# Q32M210 register map
File version: 1.0
Precision 32-bit mixed signal microcontroller
Registers are 32-bit, read-write, no defined reset value unless marked. A register's access mark holds for its fields unless they carry their own. Offsets are from the block's base; lines under a group give offsets from that group; [hi:lo] are bit positions; {n}, {i} and the like mark numbered series; 'fields as' and 'values as' point back to an identical list; <NAME> marks a mode.

## Memory map
0x40000008 Analog_Front-End blocks up to offset 0xF4
0x40000200 DMA_Controller_Configuration_and_Control blocks up to offset 0x94
0x40000300 UART0_Interface_Configuration_and_Control size 0x14
0x40000400 UART1_Interface_Configuration_and_Control size 0x14
0x40000500 GPIO_and_LCD_Driver_Configuration_and_Control blocks up to offset 0x70
0x40000600 SPI0_Interface_Configuration_and_Control size 0x18
0x40000700 SPI1_Interface_Configuration_and_Control size 0x18
0x40000800 PCM_Interface_Configuration_and_Control size 0xC
0x40000900 I2C_Interface_Configuration_and_Control blocks up to offset 0x20
0x40000A00 CRC_Generator_Control size 0x1C
0x40000B00 USB_Interface size 0x4
0x40000C00 Timer_0_to_3_Configuration_and_Control size 0x14
0x40000D00 Watchdog_Timer_Configuration_and_Control size 0x8
0x40000E00 Clock_Configuration size 0x28
0x40000F04 Flash_Update_Control blocks up to offset 0x14
0x40001784 USB_Interface_Configuration_and_Control blocks up to offset 0x6C
0xE000E004 Nested_Vector_Interrupt_Controller blocks up to offset 0xF00
0xE000E010 SYSTICK_Timer size 0x10
0xE000EDF0 Debug_Controller size 0x10

## UART0_Interface_Configuration_and_Control
Base 0x40000300
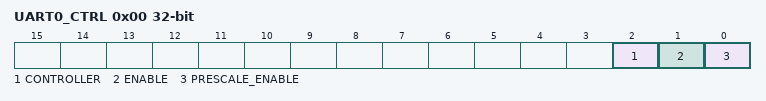
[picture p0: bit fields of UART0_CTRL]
0x00 UART0_CTRL — UART0 Control and Configuration
  [2] CONTROLLER — Select whether data transfer will be controlled by the ARM Cortex-M3 processor or the DMA for UART0
    0=UART0_CONTROLLER_CM3 (The ARM Cortex-M3 controls data transfers using UART0); 1=UART0_CONTROLLER_DMA (The DMA controls data transfers using UART0)
  [1] ENABLE — Enable or disable UART0
    0=UART0_DISABLE (Disable the UART0 interface); 1=UART0_ENABLE (Enable the UART0 interface)
  [0] PRESCALE_ENABLE — Enable or disable a prescale of the supplied UART clock by 12
    0=UART0_PRESCALE_DISABLE (Disable the prescaling division of the supplied UART clock by 12); 1=UART0_PRESCALE_ENABLE (Enable a prescaling division of the supplied UART clock by 12)
0x04 UART0_SPEED_CTRL — UART0 Baud Rate Configuration
  [15:0] UART0_SPEED_CTRL — Configure the UART0 baud rate (divided from RCLK, potentially including a prescaling divisor of 12 based on UART0_CTRL_PRESCALE_ENABLE in UART0_CTRL)
0x08 UART0_STATUS
  [1] OVERRUN_STATUS — Indicate that an overrun has occurred when receiving data on the UART0 interface
    0=UART0_OVERRUN_FALSE (UART0 no input overrun detected); 1=UART0_OVERRUN_TRUE (UART0 input overrun detected); 1=UART0_OVERRUN_CLEAR (Clear the UART0 overrun bit)
0x0C UART0_TXDATA — UART0 Transmit Data
  [7:0] UART0_TXDATA — Byte of data to transmit over the UART interface
0x10 UART0_RXDATA — UART0 Receive Data
  [7:0] UART0_RXDATA — Byte of data received from the UART interface

## UART1_Interface_Configuration_and_Control
Base 0x40000400
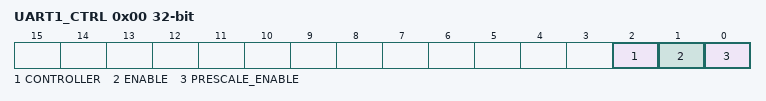
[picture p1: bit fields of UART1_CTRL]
0x00 UART1_CTRL — UART1 Control and Configuration
  [2] CONTROLLER — Select whether data transfer will be controlled by the ARM Cortex-M3 processor or the DMA for UART1
    0=UART1_CONTROLLER_CM3 (The ARM Cortex-M3 controls data transfers using UART1); 1=UART1_CONTROLLER_DMA (The DMA controls data transfers using UART1)
  [1] ENABLE — Enable or disable UART1
    0=UART1_DISABLE (Disable the UART1 interface); 1=UART1_ENABLE (Enable the UART1 interface)
  [0] PRESCALE_ENABLE — Enable or disable a prescale of the supplied UART clock by 12
    0=UART1_PRESCALE_DISABLE (Disable the prescaling division of the supplied UART clock by 12); 1=UART1_PRESCALE_ENABLE (Enable a prescaling division of the supplied UART clock by 12)
0x04 UART1_SPEED_CTRL — UART1 Baud Rate Configuration
  [15:0] UART1_SPEED_CTRL — Configure the UART1 baud rate (divided from RCLK, potentially including a prescaling divisor of 12 based on UART1_CTRL_PRESCALE_ENABLE in UART1_CTRL)
0x08 UART1_STATUS
  [1] OVERRUN_STATUS — Indicate that an overrun has occurred when receiving data on the UART1 interface
    0=UART1_OVERRUN_FALSE (UART1 no input overrun detected); 1=UART1_OVERRUN_TRUE (UART1 input overrun detected); 1=UART1_OVERRUN_CLEAR (Clear the UART1 overrun bit)
0x0C UART1_TXDATA — UART1 Transmit Data
  [7:0] UART1_TXDATA — Byte of data to transmit over the UART interface
0x10 UART1_RXDATA — UART1 Receive Data
  [7:0] UART1_RXDATA — Byte of data received from the UART interface
